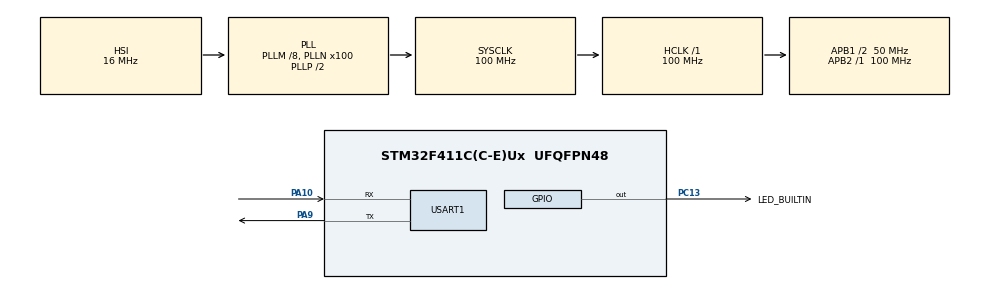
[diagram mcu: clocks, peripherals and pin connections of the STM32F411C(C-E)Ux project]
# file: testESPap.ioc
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Mcu.Family=STM32F4
Mcu.Name=STM32F411C(C-E)Ux
Mcu.Package=UFQFPN48
NVIC.PriorityGroup=NVIC_PRIORITYGROUP_4
NVIC.USART1_IRQn=true\:0\:0\:false\:false\:true\:true\:true\:true
PA10.Mode=Asynchronous
PA10.Signal=USART1_RX
PA13.Mode=Serial_Wire
PA13.Signal=SYS_JTMS-SWDIO
PA14.Mode=Serial_Wire
PA14.Signal=SYS_JTCK-SWCLK
PA9.Mode=Asynchronous
PA9.Signal=USART1_TX
PC13-ANTI_TAMP.GPIO_Label=LED_BUILTIN
PC13-ANTI_TAMP.Signal=GPIO_Output
PC14-OSC32_IN.Mode=LSE-External-Oscillator
PC14-OSC32_IN.Signal=RCC_OSC32_IN
PC15-OSC32_OUT.Mode=LSE-External-Oscillator
PC15-OSC32_OUT.Signal=RCC_OSC32_OUT
PH0\ -\ OSC_IN.Mode=HSE-External-Oscillator
PH0\ -\ OSC_IN.Signal=RCC_OSC_IN
PH1\ -\ OSC_OUT.Mode=HSE-External-Oscillator
PH1\ -\ OSC_OUT.Signal=RCC_OSC_OUT
ProjectManager.HeapSize=0x200
ProjectManager.StackSize=0x400
ProjectManager.TargetToolchain=STM32CubeIDE
RCC.48MHZClocksFreq_Value=50000000
RCC.AHBFreq_Value=100000000
RCC.APB1CLKDivider=RCC_HCLK_DIV2
RCC.APB1Freq_Value=50000000
RCC.APB1TimFreq_Value=100000000
RCC.APB2Freq_Value=100000000
RCC.APB2TimFreq_Value=100000000
RCC.CortexFreq_Value=100000000
RCC.HCLKFreq_Value=100000000
RCC.HSE_VALUE=25000000
RCC.HSI_VALUE=16000000
RCC.PLLM=8
RCC.PLLN=100
RCC.SYSCLKFreq_VALUE=100000000
RCC.SYSCLKSource=RCC_SYSCLKSOURCE_PLLCLK
RCC.VCOOutputFreq_Value=200000000
USART1.VirtualMode=VM_ASYNC
board=custom

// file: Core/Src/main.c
/* USER CODE BEGIN Header */
/**
  ******************************************************************************
  * @file           : main.c
  * @brief          : Main program body
  ******************************************************************************
  * @attention
  *
  * Copyright (c) 2025 STMicroelectronics.
  * All rights reserved.
  *
  * This software is licensed under terms that can be found in the LICENSE file
  * in the root directory of this software component.
  * If no LICENSE file comes with this software, it is provided AS-IS.
  *
  ******************************************************************************
  */
/* USER CODE END Header */
#include "main.h"

/* USER CODE BEGIN Includes */
#include "string.h"
#include "stdio.h"
/* USER CODE END Includes */

UART_HandleTypeDef huart1;

void SystemClock_Config(void);
static void MX_GPIO_Init(void);
static void MX_USART1_UART_Init(void);

int main(void)
{

  /* MCU Configuration--------------------------------------------------------*/

  /* Reset of all peripherals, Initializes the Flash interface and the Systick. */
  HAL_Init();

  /* Configure the system clock */
  SystemClock_Config();

  /* Initialize all configured peripherals */
  MX_GPIO_Init();
  MX_USART1_UART_Init();
  /* USER CODE BEGIN 2 */
  uint8_t rxBuffer[512] = {0};
    uint8_t ATisOK;
    int channel;
    int onoff;
    int led = 1;
    char ATcommand[64];
    char ATcommandB[1024];
    char ATcommandN[100];
    char ATcommandF[100];
    char ATcommandT[16];
    sprintf(ATcommandB,"<!DOCTYPE html><html>\n<head>\n\
    <title>STM32 - ESP8266</title>\n<link href=\"data:image/x-icon;base64,\
    A\" rel=\"icon\" type=\"image/x-icon\"><style>\nhtml {\
    display: inline-block; margin: 0px auto; text-align: center;}\n\
    body{margin-top: 50px;}\n.button {display: block;\n\
    width: 70px;\nbackground-color: #008000;\nborder: none;\ncolor: white;\n\
    padding: 14px 28px;\ntext-decoration: none;\nfont-size: 24px;\n\
    margin: 0px auto 36px; \nborder-radius: 5px;}\n\
    .button-on {background-color: #008000;}\n.button-on:active\
    {background-color: #008000;}\n.button-off {background-color: #808080;}\n\
    .button-off:active {background-color: #808080;}\n\
    p {font-size: 14px;color: #808080;margin-bottom: 20px;}\n\
    </style>\n</head>\n<body>\n<h1>STM32 - ESP8266</h1>");
    sprintf(ATcommandN,"<p>Light is currently on\
    </p><a class=\"button button-off\" href=\"/lightoff\">OFF</a>");
    sprintf(ATcommandF,"<p>Light is currently off\
    </p><a class=\"button button-on\" href=\"/lighton\">ON</a>");
    sprintf(ATcommandT,"</body></html>");
    int countB = strlen(ATcommandB);
    int countN = strlen(ATcommandN);
    int countF = strlen(ATcommandF);
    int countT = strlen(ATcommandT);

    sprintf(ATcommand,"AT+RST\r\n");
    memset(rxBuffer,0,sizeof(rxBuffer));
    HAL_UART_Transmit(&huart1,(uint8_t *)ATcommand,strlen(ATcommand),1000);
    HAL_UART_Receive (&huart1, rxBuffer, 512, 100);
    HAL_Delay(500);

    ATisOK = 0;
    while(!ATisOK){
      sprintf(ATcommand,"AT+CWMODE_CUR=2\r\n");
        memset(rxBuffer,0,sizeof(rxBuffer));
        HAL_UART_Transmit(&huart1,(uint8_t *)ATcommand,strlen(ATcommand),1000);
        HAL_UART_Receive (&huart1, rxBuffer, 512, 1000);
      if(strstr((char *)rxBuffer,"OK")){
        ATisOK = 1;
      }
      HAL_Delay(500);
    }

    ATisOK = 0;
    while(!ATisOK){
      sprintf(ATcommand,"AT+CWSAP_CUR=\"STM32\",\"12345678\",1,3,4,0\r\n");
        memset(rxBuffer,0,sizeof(rxBuffer));
        HAL_UART_Transmit(&huart1,(uint8_t *)ATcommand,strlen(ATcommand),1000);
        HAL_UART_Receive (&huart1, rxBuffer, 512, 1000);
      if(strstr((char *)rxBuffer,"OK")){
        ATisOK = 1;
      }
      HAL_Delay(500);
    }

    ATisOK = 0;
    while(!ATisOK){
      sprintf(ATcommand,"AT+CIPAP_CUR=\"192.168.51.1\"\r\n");
      memset(rxBuffer,0,sizeof(rxBuffer));
      HAL_UART_Transmit(&huart1,(uint8_t *)ATcommand,strlen(ATcommand),1000);
      HAL_UART_Receive (&huart1, rxBuffer, 512, 1000);
      if(strstr((char *)rxBuffer,"OK")){
        ATisOK = 1;
      }
      HAL_Delay(500);
    }

    ATisOK = 0;
    while(!ATisOK){
      sprintf(ATcommand,"AT+CIPMUX=1\r\n");
        memset(rxBuffer,0,sizeof(rxBuffer));
        HAL_UART_Transmit(&huart1,(uint8_t *)ATcommand,strlen(ATcommand),1000);
        HAL_UART_Receive (&huart1, rxBuffer, 512, 1000);
        if(strstr((char *)rxBuffer,"OK")){
          ATisOK = 1;
        }
        HAL_Delay(500);
    }

    ATisOK = 0;
    while(!ATisOK){
      sprintf(ATcommand,"AT+CIPSERVER=1,80\r\n");
      memset(rxBuffer,0,sizeof(rxBuffer));
      HAL_UART_Transmit(&huart1,(uint8_t *)ATcommand,strlen(ATcommand),1000);
      HAL_UART_Receive (&huart1, rxBuffer, 512, 1000);
      if(strstr((char *)rxBuffer,"OK")){
          ATisOK = 1;
      }
      HAL_Delay(500);
    }
  /* USER CODE END 2 */

  /* Infinite loop */
  /* USER CODE BEGIN WHILE */
  while (1)
  {
	  memset(rxBuffer,0,sizeof(rxBuffer));
	      HAL_UART_Receive (&huart1, rxBuffer, 512, 1000);
	      if(strstr((char *)rxBuffer,"+IPD,0")) channel = 0;
	      else if(strstr((char *)rxBuffer,"+IPD,1")) channel = 1;
	      else if(strstr((char *)rxBuffer,"+IPD,2")) channel = 2;
	      else if(strstr((char *)rxBuffer,"+IPD,3")) channel = 3;
	      else if(strstr((char *)rxBuffer,"+IPD,4")) channel = 4;
	      else if(strstr((char *)rxBuffer,"+IPD,5")) channel = 5;
	      else if(strstr((char *)rxBuffer,"+IPD,6")) channel = 6;
	      else if(strstr((char *)rxBuffer,"+IPD,7")) channel = 7;
	      else channel = 100;

	      if(strstr((char *)rxBuffer,"GET /lighton")) onoff = 0;
	      else if(strstr((char *)rxBuffer,"GET /lightoff")) onoff = 1;
	      else onoff = led;

	      if(channel<8 && onoff == 1)
	      {
	        HAL_GPIO_WritePin(GPIOC, GPIO_PIN_13, GPIO_PIN_SET);
	        led = 1;
	        sprintf(ATcommand,"AT+CIPSEND=%d,%d\r\n",channel,countB+countF+countT);
	        memset(rxBuffer,0,sizeof(rxBuffer));
	        HAL_UART_Transmit(&huart1,(uint8_t *)ATcommand,strlen(ATcommand),1000);
	        HAL_UART_Receive (&huart1, rxBuffer, 512, 100);
	        if(strstr((char *)rxBuffer,">"))
	        {
	          memset(rxBuffer,0,sizeof(rxBuffer));
	            HAL_UART_Transmit(&huart1,(uint8_t *)ATcommandB,countB,1000);
	            HAL_UART_Transmit(&huart1,(uint8_t *)ATcommandF,countF,1000);
	            HAL_UART_Transmit(&huart1,(uint8_t *)ATcommandT,countT,1000);
	           HAL_UART_Receive (&huart1, rxBuffer, 512, 100);
	        }
	        sprintf(ATcommand,"AT+CIPCLOSE=%d\r\n",channel);
	        memset(rxBuffer,0,sizeof(rxBuffer));
	        HAL_UART_Transmit(&huart1,(uint8_t *)ATcommand,strlen(ATcommand),1000);
	        HAL_UART_Receive (&huart1, rxBuffer, 512, 100);
	        channel=100;
	      }
	      else if(channel<8 && onoff == 0)
	      {
	        HAL_GPIO_WritePin(GPIOC, GPIO_PIN_13, GPIO_PIN_RESET);
	        led = 0;
	        sprintf(ATcommand,"AT+CIPSEND=%d,%d\r\n",channel,countB+countN+countT);
	        memset(rxBuffer,0,sizeof(rxBuffer));
	        HAL_UART_Transmit(&huart1,(uint8_t *)ATcommand,strlen(ATcommand),1000);
	        HAL_UART_Receive (&huart1, rxBuffer, 512, 100);
	        if(strstr((char *)rxBuffer,">"))
	        {
	          memset(rxBuffer,0,sizeof(rxBuffer));
	            HAL_UART_Transmit(&huart1,(uint8_t *)ATcommandB,countB,1000);
	            HAL_UART_Transmit(&huart1,(uint8_t *)ATcommandN,countN,1000);
	            HAL_UART_Transmit(&huart1,(uint8_t *)ATcommandT,countT,1000);
	            HAL_UART_Receive (&huart1, rxBuffer, 512, 100);
	        }
	        sprintf(ATcommand,"AT+CIPCLOSE=%d\r\n",channel);
	        memset(rxBuffer,0,sizeof(rxBuffer));
	        HAL_UART_Transmit(&huart1,(uint8_t *)ATcommand,strlen(ATcommand),1000);
	        HAL_UART_Receive (&huart1, rxBuffer, 512, 100);
	        channel=100;
	      }
	      /* USER CODE END WHILE */

	      /* USER CODE BEGIN 3 */
    /* USER CODE END WHILE */

    /* USER CODE BEGIN 3 */
  }
  /* USER CODE END 3 */
}

void SystemClock_Config(void)
{
  RCC_OscInitTypeDef RCC_OscInitStruct = {0};
  RCC_ClkInitTypeDef RCC_ClkInitStruct = {0};

  /** Configure the main internal regulator output voltage
  */
  __HAL_RCC_PWR_CLK_ENABLE();
  __HAL_PWR_VOLTAGESCALING_CONFIG(PWR_REGULATOR_VOLTAGE_SCALE1);

  /** Initializes the RCC Oscillators according to the specified parameters
  * in the RCC_OscInitTypeDef structure.
  */
  RCC_OscInitStruct.OscillatorType = RCC_OSCILLATORTYPE_HSI;
  RCC_OscInitStruct.HSIState = RCC_HSI_ON;
  RCC_OscInitStruct.HSICalibrationValue = RCC_HSICALIBRATION_DEFAULT;
  RCC_OscInitStruct.PLL.PLLState = RCC_PLL_ON;
  RCC_OscInitStruct.PLL.PLLSource = RCC_PLLSOURCE_HSI;
  RCC_OscInitStruct.PLL.PLLM = 8;
  RCC_OscInitStruct.PLL.PLLN = 100;
  RCC_OscInitStruct.PLL.PLLP = RCC_PLLP_DIV2;
  RCC_OscInitStruct.PLL.PLLQ = 4;
  if (HAL_RCC_OscConfig(&RCC_OscInitStruct) != HAL_OK)
  {
    Error_Handler();
  }

  /** Initializes the CPU, AHB and APB buses clocks
  */
  RCC_ClkInitStruct.ClockType = RCC_CLOCKTYPE_HCLK|RCC_CLOCKTYPE_SYSCLK
                              |RCC_CLOCKTYPE_PCLK1|RCC_CLOCKTYPE_PCLK2;
  RCC_ClkInitStruct.SYSCLKSource = RCC_SYSCLKSOURCE_PLLCLK;
  RCC_ClkInitStruct.AHBCLKDivider = RCC_SYSCLK_DIV1;
  RCC_ClkInitStruct.APB1CLKDivider = RCC_HCLK_DIV2;
  RCC_ClkInitStruct.APB2CLKDivider = RCC_HCLK_DIV1;

  if (HAL_RCC_ClockConfig(&RCC_ClkInitStruct, FLASH_LATENCY_3) != HAL_OK)
  {
    Error_Handler();
  }
}

static void MX_USART1_UART_Init(void)
{

  huart1.Instance = USART1;
  huart1.Init.BaudRate = 115200;
  huart1.Init.WordLength = UART_WORDLENGTH_8B;
  huart1.Init.StopBits = UART_STOPBITS_1;
  huart1.Init.Parity = UART_PARITY_NONE;
  huart1.Init.Mode = UART_MODE_TX_RX;
  huart1.Init.HwFlowCtl = UART_HWCONTROL_NONE;
  huart1.Init.OverSampling = UART_OVERSAMPLING_16;
  if (HAL_UART_Init(&huart1) != HAL_OK)
  {
    Error_Handler();
  }

}

static void MX_GPIO_Init(void)
{
  GPIO_InitTypeDef GPIO_InitStruct = {0};

  /* GPIO Ports Clock Enable */
  __HAL_RCC_GPIOC_CLK_ENABLE();
  __HAL_RCC_GPIOH_CLK_ENABLE();
  __HAL_RCC_GPIOA_CLK_ENABLE();

  /*Configure GPIO pin Output Level */
  HAL_GPIO_WritePin(LED_BUILTIN_GPIO_Port, LED_BUILTIN_Pin, GPIO_PIN_RESET);

  /*Configure GPIO pin : LED_BUILTIN_Pin */
  GPIO_InitStruct.Pin = LED_BUILTIN_Pin;
  GPIO_InitStruct.Mode = GPIO_MODE_OUTPUT_PP;
  GPIO_InitStruct.Pull = GPIO_NOPULL;
  GPIO_InitStruct.Speed = GPIO_SPEED_FREQ_LOW;
  HAL_GPIO_Init(LED_BUILTIN_GPIO_Port, &GPIO_InitStruct);

}

void Error_Handler(void)
{
  __disable_irq();
  while (1)
  {
  }
}
